# nrf7140_secure register map
Vendor: Nordic Semiconductor; Series: nRF71; File version: 1
CPU: CM33 r0p4, little endian, MPU, no FPU, 3 interrupt priority bits, 480 interrupts, 8 SAU regions
Registers are 32-bit, read-write, reset 0x0 unless marked. A register's access mark holds for its fields unless they carry their own. Offsets are from the block's base; [hi:lo] are bit positions; lines under a group give offsets from that group; {n}, {i} and the like mark numbered series; 'fields as' and 'values as' point back to an identical list.

## ROMC_NS — ROM Controller 0
Base 0x41005000
Same registers: ROMC_S 0x51005000
0x500 POWER group — Unspecified
  0x00 CONTROL reset 0x1 — ROM power control register.
    [0] MEM0 — Keep the ROM block MEM[0] on or off when in System ON mode.
      0=Off (Power down); 1=On (Power up)

## CRACEN_S — CRACEN
Base 0x51006000
0x100 EVENTS_CRYPTOMASTER — Event indicating that interrupt triggered at Cryptomaster
  [0] EVENTS_CRYPTOMASTER
    0=NotGenerated (Event not generated); 1=Generated (Event generated)
0x104 EVENTS_RNG — Event indicating that interrupt triggered at RNG
  [0] EVENTS_RNG
    values as EVENTS_CRYPTOMASTER.EVENTS_CRYPTOMASTER
0x108 EVENTS_PKEIKG — Event indicating that interrupt triggered at PKE or IKG
  [0] EVENTS_PKEIKG
    values as EVENTS_CRYPTOMASTER.EVENTS_CRYPTOMASTER
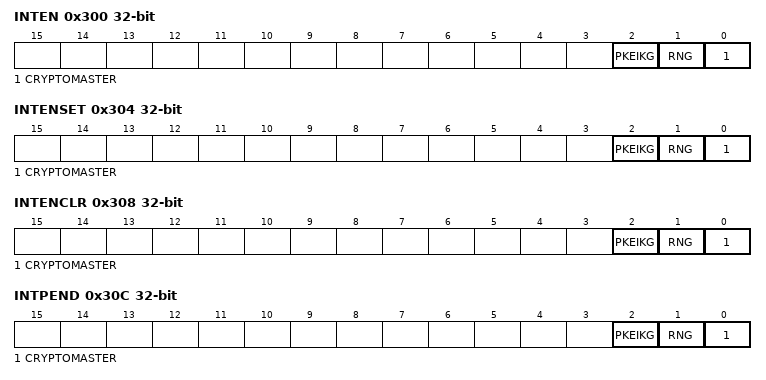
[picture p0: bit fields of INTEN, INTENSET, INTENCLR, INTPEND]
0x300 INTEN — Enable or disable interrupt
  [all] fields
    0=Disabled; 1=Enabled
  [2] PKEIKG — Enable or disable interrupt for event PKEIKG
  [1] RNG — Enable or disable interrupt for event RNG
  [0] CRYPTOMASTER — Enable or disable interrupt for event CRYPTOMASTER
0x304 INTENSET — Enable interrupt
  [all] fields
    on read: 0=Disabled (Read: Disabled); 1=Enabled (Read: Enabled) | on write: 1=Set (Enable)
  [2] PKEIKG — Write '1' to enable interrupt for event PKEIKG
  [1] RNG — Write '1' to enable interrupt for event RNG
  [0] CRYPTOMASTER — Write '1' to enable interrupt for event CRYPTOMASTER
0x308 INTENCLR — Disable interrupt
  [all] fields
    on read: 0=Disabled (Read: Disabled); 1=Enabled (Read: Enabled) | on write: 1=Clear (Disable)
  [2] PKEIKG — Write '1' to disable interrupt for event PKEIKG
  [1] RNG — Write '1' to disable interrupt for event RNG
  [0] CRYPTOMASTER — Write '1' to disable interrupt for event CRYPTOMASTER
0x30C INTPEND ro — Pending interrupts
  [all] fields
    on read: 0=NotPending (Read: Not pending); 1=Pending (Read: Pending)
  [2] PKEIKG — Read pending status of interrupt for event PKEIKG
  [1] RNG — Read pending status of interrupt for event RNG
  [0] CRYPTOMASTER — Read pending status of interrupt for event CRYPTOMASTER
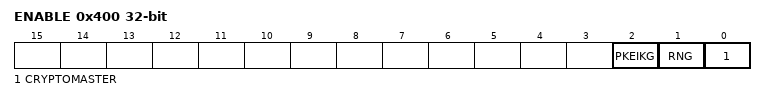
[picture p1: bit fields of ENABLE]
0x400 ENABLE — Enable CRACEN peripheral modules.
  [2] PKEIKG — Enable PKE and IKG
    0=Disabled (PKE and IKG disabled.); 1=Enabled (PKE and IKG enabled.)
  [1] RNG — Enable RNG
    0=Disabled (RNG disabled.); 1=Enabled (RNG enabled.)
  [0] CRYPTOMASTER — Enable cryptomaster
    0=Disabled (Cryptomaster disabled.); 1=Enabled (Cryptomaster enabled.)
0x404 PROTECTEDRAMLOCK — Lock the access to the protected RAM.
  [0] ENABLE — Enable the lock
    0=Disabled (Lock disabled.); 1=Enabled (Lock enabled.)
0x404 SEEDRAMLOCK (alternate view of PROTECTEDRAMLOCK) — Lock the access to the RAM used for the seed.
  fields as PROTECTEDRAMLOCK
{0x408+4i} SEED[{i}] (i=0..11) wo — Description collection: Seed word [n] for symmetric and asymmetric key generation.
  [31:0] VAL — Seed value

## PCGCS000_NS — PCGCSlave 0
Base 0x5100A000
Same registers: PCGCS000_S 0x5100A000 (alternate view of PCGCS000_NS), PCGCS010_NS 0x5101A000, PCGCS010_S 0x5101A000 (alternate view of PCGCS010_NS)
{0xC00+4i} PENALTY[{i}] (i=0..1) reset 0xFFFFFFFC — Description collection: Penalty level for power/clock pair n. When FULL_PCP_ZERO feature is not supported, PENALTY[0] address overlaps the PENALTY0 address and register description for PENALTY[0] is not valid.
  [1:0] PENALTY — Penalty level
0xC00 PENALTY0 (alternate view of PENALTY[*]) — Penalty level for power/clock pair 0. The register description is valid only when FULL_PCP_ZERO feature is not supported
  [1:0] PENALTY ro — Penalty level
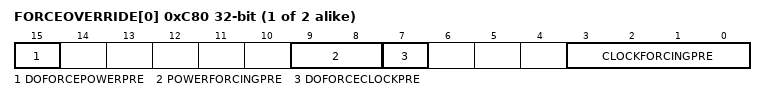
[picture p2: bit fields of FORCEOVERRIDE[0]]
{0xC80+4i} FORCEOVERRIDE[{i}] (i=0..1) — Description collection: Force override of power/clock pair n.
  [15] DOFORCEPOWERPRE, [9:8] POWERFORCINGPRE, [7] DOFORCECLOCKPRE, [3:0] CLOCKFORCINGPRE

## GLOBAL_PCGCSBUS_NS — PCGCSlave
Base 0x4900CF00; alternate view of GLOBAL_GFXPLLPM_NS
Registers as PCGCS000_NS.
